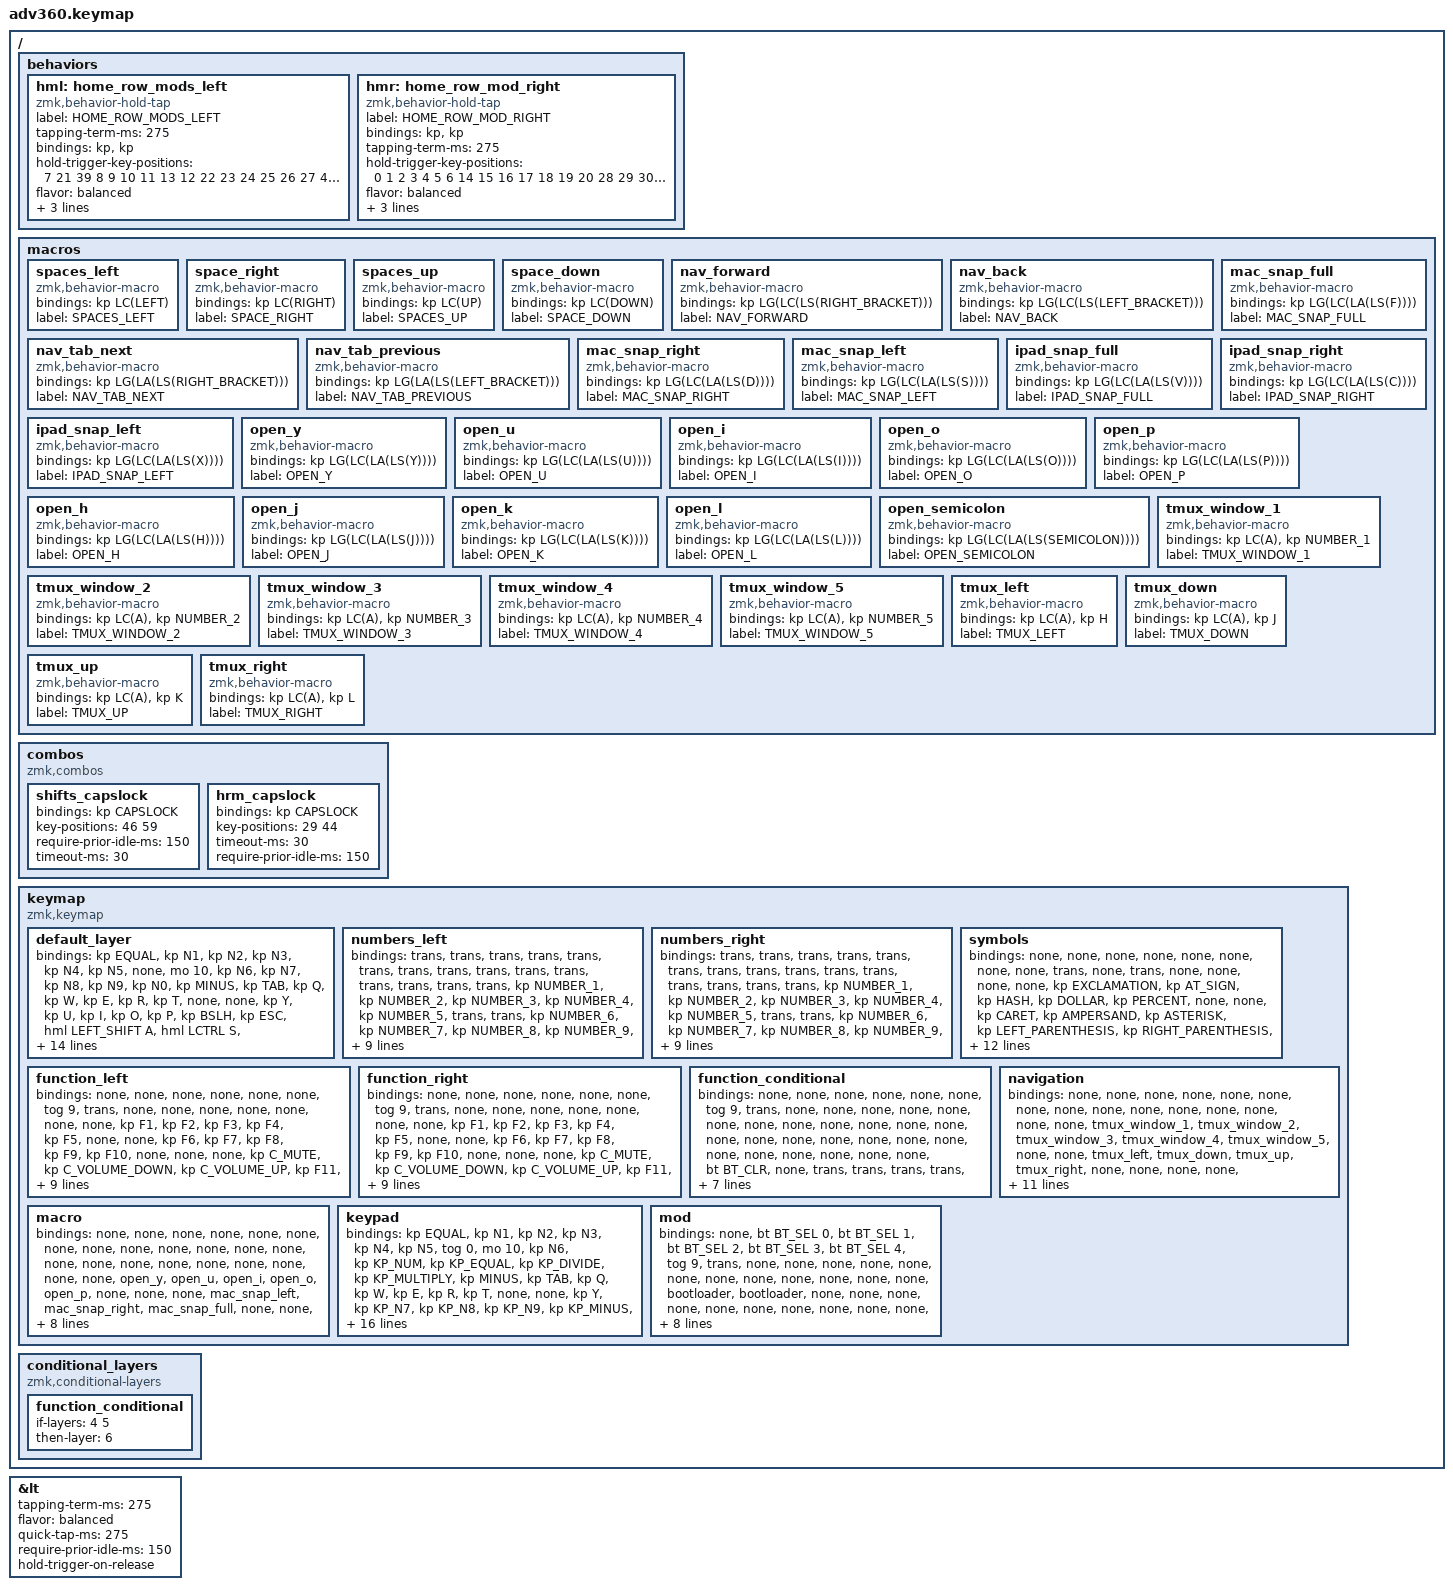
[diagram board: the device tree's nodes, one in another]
/*
 * Copyright (c) 2020 The ZMK Contributors
 *
 * SPDX-License-Identifier: MIT
 */
/* THIS FILE WAS GENERATED!
 *
 * This file was generated automatically. You may or may not want to
 * edit it directly.
 */

#include <behaviors.dtsi>
#include <dt-bindings/zmk/backlight.h>
#include <dt-bindings/zmk/bt.h>
#include <dt-bindings/zmk/keys.h>
#include <dt-bindings/zmk/rgb.h>

&lt {
    tapping-term-ms = <275>;
    flavor = "balanced";
    quick-tap-ms = <275>;
    require-prior-idle-ms = <150>;
    hold-trigger-on-release;
};

/ {
    behaviors {
        #include "macros.dtsi"
    #include "version.dtsi"

        hml: home_row_mods_left {
            compatible = "zmk,behavior-hold-tap";
            label = "HOME_ROW_MODS_LEFT";
            #binding-cells = <2>;
            tapping-term-ms = <275>;
            bindings = <&kp>, <&kp>;

            hold-trigger-key-positions = <7 21 39 8 9 10 11 13 12 22 23 24 25 26 27 45 43 41 40 42 54 55 56 57 58 44 59 75 74 73 72 38 37 53 69 70 68 7 8 9 10 21 22 23 24 37 38 39 40 41 42 54 55 56 71 72 7 8 9 10 11 12 13 21 22 23 24 25 26 27 37 38 39 40 41 42 43 44 45 53 54 55 56 57 58 59 68 69 70 71 72 73 74 75>;
            flavor = "balanced";
            quick-tap-ms = <275>;
            require-prior-idle-ms = <150>;
            hold-trigger-on-release;
        };

        hmr: home_row_mod_right {
            compatible = "zmk,behavior-hold-tap";
            label = "HOME_ROW_MOD_RIGHT";
            #binding-cells = <2>;
            bindings = <&kp>, <&kp>;

            tapping-term-ms = <275>;
            hold-trigger-key-positions = <0 1 2 3 4 5 6 14 15 16 17 18 19 20 28 29 30 31 32 33 34 35 36 46 47 48 49 50 51 52 60 61 62 63 64 65 66 67>;
            flavor = "balanced";
            quick-tap-ms = <275>;
            require-prior-idle-ms = <150>;
            hold-trigger-on-release;
        };
    };

    macros {
        spaces_left: spaces_left {
            compatible = "zmk,behavior-macro";
            #binding-cells = <0>;
            bindings = <&kp LC(LEFT)>;
            label = "SPACES_LEFT";
        };

        space_right: space_right {
            compatible = "zmk,behavior-macro";
            #binding-cells = <0>;
            bindings = <&kp LC(RIGHT)>;
            label = "SPACE_RIGHT";
        };

        spaces_up: spaces_up {
            compatible = "zmk,behavior-macro";
            #binding-cells = <0>;
            bindings = <&kp LC(UP)>;
            label = "SPACES_UP";
        };

        space_down: space_down {
            compatible = "zmk,behavior-macro";
            #binding-cells = <0>;
            bindings = <&kp LC(DOWN)>;
            label = "SPACE_DOWN";
        };

        nav_forward: nav_forward {
            compatible = "zmk,behavior-macro";
            #binding-cells = <0>;
            bindings = <&kp LG(LC(LS(RIGHT_BRACKET)))>;
            label = "NAV_FORWARD";
        };

        nav_back: nav_back {
            compatible = "zmk,behavior-macro";
            #binding-cells = <0>;
            bindings = <&kp LG(LC(LS(LEFT_BRACKET)))>;
            label = "NAV_BACK";
        };

        nav_tab_next: nav_tab_next {
            compatible = "zmk,behavior-macro";
            #binding-cells = <0>;
            bindings = <&kp LG(LA(LS(RIGHT_BRACKET)))>;
            label = "NAV_TAB_NEXT";
        };

        nav_tab_previous: nav_tab_previous {
            compatible = "zmk,behavior-macro";
            #binding-cells = <0>;
            bindings = <&kp LG(LA(LS(LEFT_BRACKET)))>;
            label = "NAV_TAB_PREVIOUS";
        };

        mac_snap_full: mac_snap_full {
            compatible = "zmk,behavior-macro";
            #binding-cells = <0>;
            bindings = <&kp LG(LC(LA(LS(F))))>;
            label = "MAC_SNAP_FULL";
        };

        mac_snap_right: mac_snap_right {
            compatible = "zmk,behavior-macro";
            #binding-cells = <0>;
            bindings = <&kp LG(LC(LA(LS(D))))>;
            label = "MAC_SNAP_RIGHT";
        };

        mac_snap_left: mac_snap_left {
            compatible = "zmk,behavior-macro";
            #binding-cells = <0>;
            bindings = <&kp LG(LC(LA(LS(S))))>;
            label = "MAC_SNAP_LEFT";
        };

        ipad_snap_full: ipad_snap_full {
            compatible = "zmk,behavior-macro";
            #binding-cells = <0>;
            bindings = <&kp LG(LC(LA(LS(V))))>;
            label = "IPAD_SNAP_FULL";
        };

        ipad_snap_right: ipad_snap_right {
            compatible = "zmk,behavior-macro";
            #binding-cells = <0>;
            bindings = <&kp LG(LC(LA(LS(C))))>;
            label = "IPAD_SNAP_RIGHT";
        };

        ipad_snap_left: ipad_snap_left {
            compatible = "zmk,behavior-macro";
            #binding-cells = <0>;
            bindings = <&kp LG(LC(LA(LS(X))))>;
            label = "IPAD_SNAP_LEFT";
        };

        open_y: open_y {
            compatible = "zmk,behavior-macro";
            #binding-cells = <0>;
            bindings = <&kp LG(LC(LA(LS(Y))))>;
            label = "OPEN_Y";
        };

        open_u: open_u {
            compatible = "zmk,behavior-macro";
            #binding-cells = <0>;
            bindings = <&kp LG(LC(LA(LS(U))))>;
            label = "OPEN_U";
        };

        open_i: open_i {
            compatible = "zmk,behavior-macro";
            #binding-cells = <0>;
            bindings = <&kp LG(LC(LA(LS(I))))>;
            label = "OPEN_I";
        };

        open_o: open_o {
            compatible = "zmk,behavior-macro";
            #binding-cells = <0>;
            bindings = <&kp LG(LC(LA(LS(O))))>;
            label = "OPEN_O";
        };

        open_p: open_p {
            compatible = "zmk,behavior-macro";
            #binding-cells = <0>;
            bindings = <&kp LG(LC(LA(LS(P))))>;
            label = "OPEN_P";
        };

        open_h: open_h {
            compatible = "zmk,behavior-macro";
            #binding-cells = <0>;
            bindings = <&kp LG(LC(LA(LS(H))))>;
            label = "OPEN_H";
        };

        open_j: open_j {
            compatible = "zmk,behavior-macro";
            #binding-cells = <0>;
            bindings = <&kp LG(LC(LA(LS(J))))>;
            label = "OPEN_J";
        };

        open_k: open_k {
            compatible = "zmk,behavior-macro";
            #binding-cells = <0>;
            bindings = <&kp LG(LC(LA(LS(K))))>;
            label = "OPEN_K";
        };

        open_l: open_l {
            compatible = "zmk,behavior-macro";
            #binding-cells = <0>;
            bindings = <&kp LG(LC(LA(LS(L))))>;
            label = "OPEN_L";
        };

        open_semicolon: open_semicolon {
            compatible = "zmk,behavior-macro";
            #binding-cells = <0>;
            bindings = <&kp LG(LC(LA(LS(SEMICOLON))))>;
            label = "OPEN_SEMICOLON";
        };

        tmux_window_1: tmux_window_1 {
            compatible = "zmk,behavior-macro";
            #binding-cells = <0>;
            bindings = <&kp LC(A) &kp NUMBER_1>;
            label = "TMUX_WINDOW_1";
        };

        tmux_window_2: tmux_window_2 {
            compatible = "zmk,behavior-macro";
            #binding-cells = <0>;
            bindings = <&kp LC(A) &kp NUMBER_2>;
            label = "TMUX_WINDOW_2";
        };

        tmux_window_3: tmux_window_3 {
            compatible = "zmk,behavior-macro";
            #binding-cells = <0>;
            bindings = <&kp LC(A) &kp NUMBER_3>;
            label = "TMUX_WINDOW_3";
        };

        tmux_window_4: tmux_window_4 {
            compatible = "zmk,behavior-macro";
            #binding-cells = <0>;
            bindings = <&kp LC(A) &kp NUMBER_4>;
            label = "TMUX_WINDOW_4";
        };

        tmux_window_5: tmux_window_5 {
            compatible = "zmk,behavior-macro";
            #binding-cells = <0>;
            bindings = <&kp LC(A) &kp NUMBER_5>;
            label = "TMUX_WINDOW_5";
        };

        tmux_left: tmux_left {
            compatible = "zmk,behavior-macro";
            #binding-cells = <0>;
            bindings = <&kp LC(A) &kp H>;
            label = "TMUX_LEFT";
        };

        tmux_down: tmux_down {
            compatible = "zmk,behavior-macro";
            #binding-cells = <0>;
            bindings = <&kp LC(A) &kp J>;
            label = "TMUX_DOWN";
        };

        tmux_up: tmux_up {
            compatible = "zmk,behavior-macro";
            #binding-cells = <0>;
            bindings = <&kp LC(A) &kp K>;
            label = "TMUX_UP";
        };

        tmux_right: tmux_right {
            compatible = "zmk,behavior-macro";
            #binding-cells = <0>;
            bindings = <&kp LC(A) &kp L>;
            label = "TMUX_RIGHT";
        };
    };

    combos {
        compatible = "zmk,combos";

        shifts_capslock {
            bindings = <&kp CAPSLOCK>;
            key-positions = <46 59>;
            require-prior-idle-ms = <150>;
            timeout-ms = <30>;
        };

        hrm_capslock {
            bindings = <&kp CAPSLOCK>;
            key-positions = <29 44>;
            timeout-ms = <30>;
            require-prior-idle-ms = <150>;
        };
    };

    keymap {
        compatible = "zmk,keymap";

        default_layer {
            bindings = <
&kp EQUAL  &kp N1             &kp N2        &kp N3           &kp N4               &kp N5   &none                                                                                  &mo 10     &kp N6   &kp N7                &kp N8            &kp N9        &kp N0                 &kp MINUS
&kp TAB    &kp Q              &kp W         &kp E            &kp R                &kp T    &none                                                                                  &none      &kp Y    &kp U                 &kp I             &kp O         &kp P                  &kp BSLH
&kp ESC    &hml LEFT_SHIFT A  &hml LCTRL S  &hml LEFT_ALT D  &hml LEFT_COMMAND F  &lt 7 G  &none         &kp LEFT_ALT     &kp LEFT_COMMAND      &kp RIGHT_COMMAND  &kp RIGHT_ALT  &none      &lt 7 H  &hmr RIGHT_COMMAND J  &hmr RIGHT_ALT K  &hmr RCTRL L  &hmr RIGHT_SHIFT SEMI  &kp SQT
&kp LSHFT  &lt 4 Z            &kp X         &kp C            &kp V                &kp B                                   &kp LEFT_CONTROL      &kp RIGHT_CONTROL                            &kp N    &kp M                 &kp COMMA         &kp DOT       &lt 5 SLASH            &kp RSHFT
&mo 4      &kp GRAVE          &none         &kp LEFT         &kp RIGHT                     &lt 8 ESCAPE  &lt 1 BACKSPACE  &lt 3 DELETE          &lt 3 ENTER        &lt 2 SPACE    &lt 8 TAB           &kp DOWN              &kp UP            &kp LBKT      &kp RBKT               &mo 5
            >;
        };

        numbers_left {
            bindings = <
&trans  &trans        &trans        &trans        &trans        &trans        &trans                                                    &trans     &trans        &trans        &trans        &trans        &trans        &trans
&trans  &kp NUMBER_1  &kp NUMBER_2  &kp NUMBER_3  &kp NUMBER_4  &kp NUMBER_5  &trans                                                    &trans     &kp NUMBER_6  &kp NUMBER_7  &kp NUMBER_8  &kp NUMBER_9  &kp NUMBER_0  &trans
&trans  &trans        &trans        &trans        &trans        &trans        &trans         &trans      &trans      &trans  &trans     &trans     &trans        &trans        &trans        &trans        &trans        &trans
&trans  &trans        &trans        &trans        &trans        &trans                                   &trans      &trans                        &trans        &trans        &trans        &trans        &trans        &trans
&trans  &trans        &trans        &trans        &trans                      &kp BACKSPACE  &kp DELETE  &trans      &trans  &kp ENTER  &kp SPACE                &trans        &trans        &trans        &trans        &trans
            >;
        };

        numbers_right {
            bindings = <
&trans  &trans        &trans        &trans        &trans        &trans        &trans                                                    &trans     &trans        &trans        &trans        &trans        &trans        &trans
&trans  &kp NUMBER_1  &kp NUMBER_2  &kp NUMBER_3  &kp NUMBER_4  &kp NUMBER_5  &trans                                                    &trans     &kp NUMBER_6  &kp NUMBER_7  &kp NUMBER_8  &kp NUMBER_9  &kp NUMBER_0  &trans
&trans  &trans        &trans        &trans        &trans        &trans        &trans         &trans      &trans      &trans  &trans     &trans     &trans        &trans        &trans        &trans        &trans        &trans
&trans  &trans        &trans        &trans        &trans        &trans                                   &trans      &trans                        &trans        &trans        &trans        &trans        &trans        &trans
&trans  &trans        &trans        &trans        &trans                      &kp BACKSPACE  &kp DELETE  &trans      &trans  &kp ENTER  &kp SPACE                &trans        &trans        &trans        &trans        &trans
            >;
        };

        symbols {
            bindings = <
&none  &none            &none             &none              &none              &none           &none                                                            &none    &trans     &none          &trans                &none                  &none                  &none
&none  &kp EXCLAMATION  &kp AT_SIGN       &kp HASH           &kp DOLLAR         &kp PERCENT     &none                                                            &none    &kp CARET  &kp AMPERSAND  &kp ASTERISK          &kp LEFT_PARENTHESIS   &kp RIGHT_PARENTHESIS  &none
&none  &kp TILDE        &kp LEFT_BRACKET  &kp RIGHT_BRACKET  &kp SQT            &kp UNDERSCORE  &none       &trans         &trans          &trans     &trans     &none    &kp MINUS  &kp EQUAL      &kp LEFT_PARENTHESIS  &kp RIGHT_PARENTHESIS  &kp PIPE               &none
&none  &kp GRAVE        &kp LEFT_BRACE    &kp RIGHT_BRACE    &kp DOUBLE_QUOTES  &none                                      &trans          &trans                         &none      &kp PLUS       &kp LESS_THAN         &kp GREATER_THAN       &kp BACKSLASH          &none
&none  &none            &none             &none              &none                              &kp ESCAPE  &kp BACKSPACE  &kp DELETE      &kp ENTER  &kp SPACE  &kp TAB             &none          &none                 &none                  &none                  &none
            >;
        };

        function_left {
            bindings = <
&none   &none   &none       &none                 &none                 &none    &tog 9                                                           &trans   &none    &none     &none       &none       &none    &none
&none   &kp F1  &kp F2      &kp F3                &kp F4                &kp F5   &none                                                            &none    &kp F6   &kp F7    &kp F8      &kp F9      &kp F10  &none
&none   &none   &kp C_MUTE  &kp C_VOLUME_DOWN     &kp C_VOLUME_UP       &kp F11  &none       &trans         &trans          &trans     &trans     &none    &kp F12  &kp C_PP  &kp C_PREV  &kp C_NEXT  &none    &none
&none   &trans  &none       &kp C_BRIGHTNESS_DEC  &kp C_BRIGHTNESS_INC  &none                               &trans          &trans                         &none    &none     &none       &none       &none    &none
&trans  &none   &none       &none                 &none                          &kp ESCAPE  &kp BACKSPACE  &kp DELETE      &kp ENTER  &kp SPACE  &kp TAB           &none     &none       &none       &none    &none
            >;
        };

        function_right {
            bindings = <
&none   &none   &none       &none                 &none                 &none    &tog 9                                                           &trans   &none    &none     &none       &none       &none    &none
&none   &kp F1  &kp F2      &kp F3                &kp F4                &kp F5   &none                                                            &none    &kp F6   &kp F7    &kp F8      &kp F9      &kp F10  &none
&none   &none   &kp C_MUTE  &kp C_VOLUME_DOWN     &kp C_VOLUME_UP       &kp F11  &none       &trans         &trans          &trans     &trans     &none    &kp F12  &kp C_PP  &kp C_PREV  &kp C_NEXT  &none    &none
&none   &trans  &none       &kp C_BRIGHTNESS_DEC  &kp C_BRIGHTNESS_INC  &none                               &trans          &trans                         &none    &none     &none       &none       &trans   &none
&trans  &none   &none       &none                 &none                          &kp ESCAPE  &kp BACKSPACE  &kp DELETE      &kp ENTER  &kp SPACE  &kp TAB           &none     &none       &none       &none    &trans
            >;
        };

        function_conditional {
            bindings = <
&none   &none   &none         &none  &none  &none       &tog 9                                                           &trans   &none         &none         &none         &none         &none         &none
&none   &none   &none         &none  &none  &none       &none                                                            &none    &none         &none         &none         &none         &none         &none
&none   &none   &none         &none  &none  &bt BT_CLR  &none       &trans         &trans          &trans     &trans     &none    &bt BT_SEL 0  &bt BT_SEL 1  &bt BT_SEL 2  &bt BT_SEL 3  &bt BT_SEL 4  &none
&none   &trans  &none         &none  &none  &none                                  &trans          &trans                         &none         &none         &none         &none         &trans        &none
&trans  &none   &kp CAPSLOCK  &none  &none              &kp ESCAPE  &kp BACKSPACE  &kp DELETE      &kp ENTER  &kp SPACE  &kp TAB                &none         &none         &none         &none         &trans
            >;
        };

        navigation {
            bindings = <
&none  &none           &none           &none              &none           &none           &none                                                            &none    &none       &none          &none         &none        &none  &none
&none  &tmux_window_1  &tmux_window_2  &tmux_window_3     &tmux_window_4  &tmux_window_5  &none                                                            &none    &tmux_left  &tmux_down     &tmux_up      &tmux_right  &none  &none
&none  &none           &nav_back       &nav_tab_previous  &nav_tab_next   &nav_forward    &none       &trans         &trans          &trans     &trans     &none    &kp LEFT    &kp DOWN       &kp UP_ARROW  &kp RIGHT    &none  &none
&none  &none           &spaces_left    &spaces_up         &space_down     &space_right                               &trans          &trans                         &kp HOME    &kp PAGE_DOWN  &kp PAGE_UP   &kp END      &none  &none
&none  &none           &none           &none              &none                           &kp ESCAPE  &kp BACKSPACE  &kp DELETE      &kp ENTER  &kp SPACE  &kp TAB              &none          &none         &none        &none  &none
            >;
        };

        macro {
            bindings = <
&none  &none  &none            &none             &none            &none  &none                                       &none   &none    &none    &none    &none    &none            &none
&none  &none  &none            &none             &none            &none  &none                                       &none   &open_y  &open_u  &open_i  &open_o  &open_p          &none
&none  &none  &mac_snap_left   &mac_snap_right   &mac_snap_full   &none  &none   &trans  &trans      &trans  &trans  &none   &open_h  &open_j  &open_k  &open_l  &open_semicolon  &none
&none  &none  &ipad_snap_left  &ipad_snap_right  &ipad_snap_full  &none                  &trans      &trans                  &none    &none    &none    &none    &none            &none
&none  &none  &none            &none             &none                   &trans  &trans  &trans      &trans  &trans  &trans           &none    &none    &none    &none            &trans
            >;
        };

        keypad {
            bindings = <
&kp EQUAL  &kp N1             &kp N2               &kp N3           &kp N4               &kp N5   &tog 0                                                                               &mo 10             &kp N6   &kp KP_NUM                    &kp KP_EQUAL                &kp KP_DIVIDE             &kp KP_MULTIPLY           &kp MINUS
&kp TAB    &kp Q              &kp W                &kp E            &kp R                &kp T    &none                                                                                &none              &kp Y    &kp KP_N7                     &kp KP_N8                   &kp KP_N9                 &kp KP_MINUS              &kp BSLH
&kp ESC    &hml LEFT_SHIFT A  &hml LEFT_CONTROL S  &hml LEFT_ALT D  &hml LEFT_COMMAND F  &lt 7 G  &none         &kp LCTRL        &kp LALT              &kp RIGHT_COMMAND  &kp RCTRL    &none              &lt 7 H  &hmr RIGHT_COMMAND LS(KP_N4)  &hmr RIGHT_ALT KP_NUMBER_5  &hmr RIGHT_CONTROL KP_N6  &hmr RIGHT_SHIFT KP_PLUS  &kp SQT
&kp LSHFT  &kp Z              &kp X                &kp C            &lt 3 V              &kp B                                   &kp LEFT_CONTROL      &kp RIGHT_CONTROL                                  &kp N    &lt 7 M                       &kp KP_N2                   &kp KP_N3                 &kp KP_ENTER              &kp RSHFT
&mo 4      &kp GRAVE          &none                &kp LEFT         &kp RIGHT                     &lt 8 ESCAPE  &lt 1 BACKSPACE  &lt 3 DELETE          &lt 3 ENTER        &lt 2 SPACE  &lt 8 KP_NUMBER_0           &kp DOWN                      &kp UP                      &kp KP_DOT                &kp RBKT                  &mo 4
            >;
        };

        mod {
            bindings = <
&none  &bt BT_SEL 0  &bt BT_SEL 1  &bt BT_SEL 2  &bt BT_SEL 3  &bt BT_SEL 4  &tog 9                                                 &trans                  &none  &none       &none       &none  &none  &none
&none  &none         &none         &none         &none         &none         &bootloader                                            &bootloader             &none  &none       &none       &none  &none  &none
&none  &none         &none         &none         &none         &none         &none        &none  &none      &bt BT_CLR  &none       &rgb_ug RGB_MEFS_CMD 5  &none  &none       &none       &none  &none  &none
&none  &none         &none         &none         &macro_ver    &none                             &none      &none                                           &none  &none       &none       &none  &none  &none
&none  &none         &trans        &none         &none                       &none        &none  &none      &none       &bl BL_TOG  &rgb_ug RGB_TOG                &bl BL_INC  &bl BL_DEC  &none  &none  &none
            >;
        };
    };

    conditional_layers {
        compatible = "zmk,conditional-layers";

        function_conditional {
            if-layers = <4 5>;
            then-layer = <6>;
        };
    };
};
